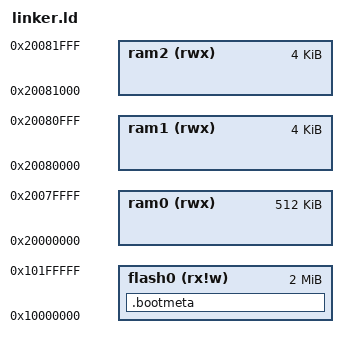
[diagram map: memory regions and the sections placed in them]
/*
 * Target CPU:  cortex_m33
 * Target Chip: RP2350
 */

/*
 * This section was auto-generated by microzig.
 */
MEMORY
{
  flash0 (rx!w) : ORIGIN = 0x10000000, LENGTH = 0x00200000
  ram0 (rwx) : ORIGIN = 0x20000000, LENGTH = 0x00080000
  ram1 (rwx) : ORIGIN = 0x20080000, LENGTH = 0x00001000
  ram2 (rwx) : ORIGIN = 0x20081000, LENGTH = 0x00001000
}

/*
 * End of auto-generated section.
 */
SECTIONS {
  .bootmeta :
  {
    __bootmeta_start__ = .;
    KEEP(*(.bootmeta))
    __bootmeta_end__ = .;
  } > flash0
}
INSERT AFTER .flash_start;

SECTIONS {
  .ram_vectors (NOLOAD) :
  {
    KEEP(*(ram_vectors))
  } > ram0
}
INSERT AFTER .bss;

SECTIONS
{
  .flash_start :
  {
    KEEP(*(microzig_flash_start))
  } > flash0

  .text :
  {
    *(.text*)
    *(.srodata*)
    *(.rodata*)
  } > flash0

  .ARM.extab : {
    *(.ARM.extab* .gnu.linkonce.armextab.*)
  } > flash0

  .ARM.exidx : {
    *(.ARM.exidx* .gnu.linkonce.armexidx.*)
  } > flash0

  .data :
  {
    microzig_data_start = .;
    *(.sdata*)
    *(.data*)
    KEEP(*(.ram_text))
    microzig_data_end = .;
  } > ram0 AT> flash0

  .bss (NOLOAD) :
  {
    microzig_bss_start = .;
    *(.sbss*)
    *(.bss*)
    microzig_bss_end = .;
  } > ram0

  .flash_end :
  {
    microzig_flash_end = .;
  } > flash0

  microzig_data_load_start = LOADADDR(.data);
}
